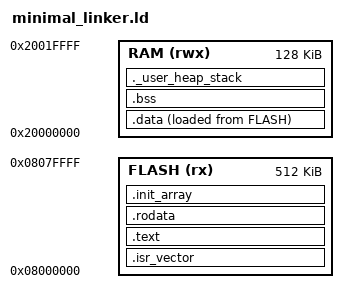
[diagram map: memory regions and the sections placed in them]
/* Minimal Linker Script Example — STM32-style */
/* This is a conceptual example for learning purposes */

ENTRY(Reset_Handler)

/* Define memory regions */
MEMORY
{
    FLASH (rx)  : ORIGIN = 0x08000000, LENGTH = 512K
    RAM   (rwx) : ORIGIN = 0x20000000, LENGTH = 128K
}

/* Initial stack pointer = top of RAM */
_estack = ORIGIN(RAM) + LENGTH(RAM);

SECTIONS
{
    /* Interrupt vector table — must be at start of Flash */
    .isr_vector :
    {
        . = ALIGN(4);
        KEEP(*(.isr_vector))
        . = ALIGN(4);
    } > FLASH

    /* Program code */
    .text :
    {
        . = ALIGN(4);
        *(.text)
        *(.text*)
        *(.glue_7)
        *(.glue_7t)
        KEEP(*(.init))
        KEEP(*(.fini))
        . = ALIGN(4);
        _etext = .;
    } > FLASH

    /* Read-only data (constants, string literals) */
    .rodata :
    {
        . = ALIGN(4);
        *(.rodata)
        *(.rodata*)
        . = ALIGN(4);
    } > FLASH

    /* C++ global constructors */
    .init_array :
    {
        PROVIDE_HIDDEN(__init_array_start = .);
        KEEP(*(SORT(.init_array.*)))
        KEEP(*(.init_array))
        PROVIDE_HIDDEN(__init_array_end = .);
    } > FLASH

    /* Initialized data — Load from Flash, run from RAM */
    _sidata = LOADADDR(.data);

    .data :
    {
        . = ALIGN(4);
        _sdata = .;
        *(.data)
        *(.data*)
        . = ALIGN(4);
        _edata = .;
    } > RAM AT> FLASH

    /* Zero-initialized data — RAM only */
    .bss :
    {
        . = ALIGN(4);
        _sbss = .;
        __bss_start__ = _sbss;
        *(.bss)
        *(.bss*)
        *(COMMON)
        . = ALIGN(4);
        _ebss = .;
        __bss_end__ = _ebss;
    } > RAM

    /* Heap and Stack */
    ._user_heap_stack :
    {
        . = ALIGN(8);
        PROVIDE(end = .);
        PROVIDE(_end = .);
        . = . + 0x400;    /* Min heap size: 1KB */
        . = . + 0x800;    /* Min stack size: 2KB */
        . = ALIGN(8);
    } > RAM
}
